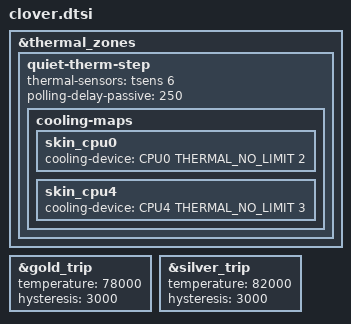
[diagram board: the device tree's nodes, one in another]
#include "mi/clover/clover-base.dtsi"
#include "xiaomi-sdm660-common.dtsi"

/* KS-SB Clover thermal fallback
 *
 * Clover's PM660 quiet-therm ADC path is not readable on the current
 * Android/Linux stack, which leaves quiet-therm-step disabled and prevents the
 * intended CPU cpufreq cooling maps from ever engaging.
 *
 * Reuse the existing two-stage cooling map, but source it from the valid TSENS
 * channel used by cpu-1-3-step.  Gold backs off first; Silver follows only if
 * the SoC keeps heating.  The original 105C CPU-isolation trips remain intact
 * as the emergency backstop.
 */
&thermal_zones {
    quiet-therm-step {
        thermal-sensors = <&tsens 6>;
        polling-delay-passive = <250>;

        /*
         * Keep step_wise gradual, but stop at the intended sustained clocks
         * for Clover's current OPP tables:
         *   Silver: state 2 -> 1.536 GHz
         *   Gold:   state 3 -> 1.747 GHz
         */
        cooling-maps {
            skin_cpu0 {
                cooling-device = <&CPU0 THERMAL_NO_LIMIT 2>;
            };

            skin_cpu4 {
                cooling-device = <&CPU4 THERMAL_NO_LIMIT 3>;
            };
        };
    };
};

&gold_trip {
    temperature = <78000>;
    hysteresis = <3000>;
};

&silver_trip {
    temperature = <82000>;
    hysteresis = <3000>;
};

